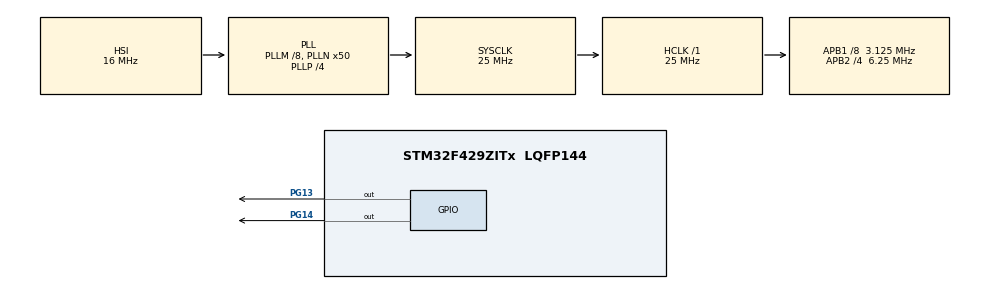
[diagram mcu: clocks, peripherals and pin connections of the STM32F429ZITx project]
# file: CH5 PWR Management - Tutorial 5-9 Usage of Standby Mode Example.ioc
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Mcu.Family=STM32F4
Mcu.Name=STM32F429ZITx
Mcu.Package=LQFP144
NVIC.PriorityGroup=NVIC_PRIORITYGROUP_0
PA0/WKUP.Mode=SYS_WakeUp0
PA0/WKUP.Signal=SYS_WKUP
PG13.Signal=GPIO_Output
PG14.Signal=GPIO_Output
ProjectManager.HeapSize=0x200
ProjectManager.StackSize=0x400
ProjectManager.TargetToolchain=STM32CubeIDE
RCC.48MHZClocksFreq_Value=14285714.285714285
RCC.AHBFreq_Value=25000000
RCC.APB1CLKDivider=RCC_HCLK_DIV8
RCC.APB1Freq_Value=3125000
RCC.APB1TimFreq_Value=6250000
RCC.APB2CLKDivider=RCC_HCLK_DIV4
RCC.APB2Freq_Value=6250000
RCC.APB2TimFreq_Value=12500000
RCC.CortexFreq_Value=25000000
RCC.HCLKFreq_Value=25000000
RCC.HSE_VALUE=8000000
RCC.HSI_VALUE=16000000
RCC.LSE_VALUE=32768
RCC.PLLM=8
RCC.PLLN=50
RCC.PLLP=RCC_PLLP_DIV4
RCC.PLLQ=7
RCC.SYSCLKFreq_VALUE=25000000
RCC.SYSCLKSource=RCC_SYSCLKSOURCE_PLLCLK
RCC.VCOOutputFreq_Value=100000000
board=STM32F429I-DISC1

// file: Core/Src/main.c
/* USER CODE BEGIN Header */
/**
  ******************************************************************************
  * @file           : main.c
  * @brief          : Main program body
  ******************************************************************************
  * @attention
  *
  * Copyright (c) 2023 STMicroelectronics.
  * All rights reserved.
  *
  * This software is licensed under terms that can be found in the LICENSE file
  * in the root directory of this software component.
  * If no LICENSE file comes with this software, it is provided AS-IS.
  *
  ******************************************************************************
  */

  /***************************** Tutorial Tags ******************************
		 Standby mode functions
		 GPIO Digital Input interrupt
		 GPIO Digital output
	 **************************************************************************/

	/* 5.6 Usage of power modes on the STM32F4Microcontroller: ***********************
	 * Tutorial 5.9: Usage of standby mode functions, in C language

    In this tutorial, we provide an example on the usage of standby mode. Here we wake up
	the CPU with the onboard button connected to PA0, toggle the onboard LEDs
	connected to pins PG13 and PG14, and then put CPU back to standby mode. To do
	so, the reader should first create an empty project and configure the LED pins of the
	STM32F4 microcontroller as output. Then, he or she should configure the button
	pin as SYS_WKUP and select the mode as “external interrupt mode with falling
	edge trigger detection.”

	***************************************************************************/
/* USER CODE END Header */
#include "main.h"

void SystemClock_Config(void);
static void MX_GPIO_Init(void);

int main(void)
{

  /* MCU Configuration--------------------------------------------------------*/

  /* Reset of all peripherals, Initializes the Flash interface and the Systick. */
  HAL_Init();

  /* Configure the system clock */
  SystemClock_Config();

  /* Initialize all configured peripherals */
  MX_GPIO_Init();
  /* USER CODE BEGIN 2 */

  HAL_GPIO_TogglePin (GPIOG , GPIO_PIN_13 );
  HAL_Delay (1000) ;
  HAL_GPIO_TogglePin (GPIOG , GPIO_PIN_14 );
  HAL_Delay (1000) ;

  __HAL_PWR_CLEAR_FLAG(PWR_FLAG_WU);
  HAL_PWR_EnableWakeUpPin(PWR_WAKEUP_PIN1);
  HAL_PWR_EnterSTANDBYMode();

  /* USER CODE END 2 */

  /* Infinite loop */
  while (1)
  {

  }
}

void SystemClock_Config(void)
{
  RCC_OscInitTypeDef RCC_OscInitStruct = {0};
  RCC_ClkInitTypeDef RCC_ClkInitStruct = {0};

  /** Configure the main internal regulator output voltage
  */
  __HAL_RCC_PWR_CLK_ENABLE();
  __HAL_PWR_VOLTAGESCALING_CONFIG(PWR_REGULATOR_VOLTAGE_SCALE3);

  /** Initializes the RCC Oscillators according to the specified parameters
  * in the RCC_OscInitTypeDef structure.
  */
  RCC_OscInitStruct.OscillatorType = RCC_OSCILLATORTYPE_HSI;
  RCC_OscInitStruct.HSIState = RCC_HSI_ON;
  RCC_OscInitStruct.HSICalibrationValue = RCC_HSICALIBRATION_DEFAULT;
  RCC_OscInitStruct.PLL.PLLState = RCC_PLL_ON;
  RCC_OscInitStruct.PLL.PLLSource = RCC_PLLSOURCE_HSI;
  RCC_OscInitStruct.PLL.PLLM = 8;
  RCC_OscInitStruct.PLL.PLLN = 50;
  RCC_OscInitStruct.PLL.PLLP = RCC_PLLP_DIV4;
  RCC_OscInitStruct.PLL.PLLQ = 7;
  if (HAL_RCC_OscConfig(&RCC_OscInitStruct) != HAL_OK)
  {
    Error_Handler();
  }

  /** Initializes the CPU, AHB and APB buses clocks
  */
  RCC_ClkInitStruct.ClockType = RCC_CLOCKTYPE_HCLK|RCC_CLOCKTYPE_SYSCLK
                              |RCC_CLOCKTYPE_PCLK1|RCC_CLOCKTYPE_PCLK2;
  RCC_ClkInitStruct.SYSCLKSource = RCC_SYSCLKSOURCE_PLLCLK;
  RCC_ClkInitStruct.AHBCLKDivider = RCC_SYSCLK_DIV1;
  RCC_ClkInitStruct.APB1CLKDivider = RCC_HCLK_DIV8;
  RCC_ClkInitStruct.APB2CLKDivider = RCC_HCLK_DIV4;

  if (HAL_RCC_ClockConfig(&RCC_ClkInitStruct, FLASH_LATENCY_0) != HAL_OK)
  {
    Error_Handler();
  }
}

static void MX_GPIO_Init(void)
{
  GPIO_InitTypeDef GPIO_InitStruct = {0};

  /* GPIO Ports Clock Enable */
  __HAL_RCC_GPIOA_CLK_ENABLE();
  __HAL_RCC_GPIOG_CLK_ENABLE();

  /*Configure GPIO pin Output Level */
  HAL_GPIO_WritePin(GPIOG, GPIO_PIN_13|GPIO_PIN_14, GPIO_PIN_RESET);

  /*Configure GPIO pins : PG13 PG14 */
  GPIO_InitStruct.Pin = GPIO_PIN_13|GPIO_PIN_14;
  GPIO_InitStruct.Mode = GPIO_MODE_OUTPUT_PP;
  GPIO_InitStruct.Pull = GPIO_NOPULL;
  GPIO_InitStruct.Speed = GPIO_SPEED_FREQ_LOW;
  HAL_GPIO_Init(GPIOG, &GPIO_InitStruct);

}

void Error_Handler(void)
{
  __disable_irq();
  while (1)
  {
  }
}
